# SN32F100 register map
Vendor: SONiX Technology Co., Ltd.; Series: SN32F100; File version: 1.3
CPU: CM0 r0p0, little endian, no MPU, no FPU, 2 interrupt priority bits
Registers are 32-bit, read-write, reset 0x0 unless marked. A register's access mark holds for its fields unless they carry their own. Offsets are from the block's base; [hi:lo] are bit positions; {n}, {i} and the like mark numbered series.

## SN_I2S — I2S
Base 0x4001A000
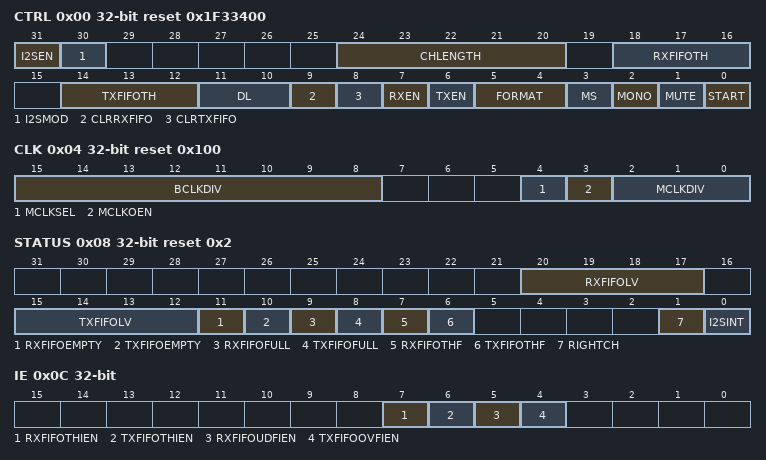
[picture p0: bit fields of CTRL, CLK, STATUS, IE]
0x00 CTRL reset 0x1F33400 — Offset:0x00 I2S Control Register
  [31] I2SEN — I2S enable
    0=Disable I2S; 1=Enable I2S
  [30] I2SMOD — I2S mode select bit
    0=I2S mode for external I2S interface; 1=Codec mode for internal I2S interface connected to ADC and DAC
  [24:20] CHLENGTH — Bit number of single channel
    {v}={v+1} bits (v=7..30); 31=32 bits (Max)
  [18:16] RXFIFOTH — Rx FIFO threshold level
    {v}=Rx FIFO threshold level={v} (v=0..7)
  [14:12] TXFIFOTH — Tx FIFO threshold level
    {v}=Tx FIFO threshold level={v} (v=0..7)
  [11:10] DL — Data length
    0=Data length=8 bits; 1=Data length=16 bits; 2=Data length=24 bits; 3=Data length=32 bits
  [9] CLRRXFIFO wo — Clear I2S RX FIFO
    0=No effect; 1=Reset Rx FIFO
  [8] CLRTXFIFO wo — Clear I2S TX FIFO
    0=No effect; 1=Reset TX FIFO
  [7] RXEN wo — Receiver enable bit
    0=Disable; 1=Enable
  [6] TXEN — Transmit enable bit
    0=Disable; 1=Enable
  [5:4] FORMAT — I2S operation format
    0=00b (Standard I2S format); 1=01b (Left-justified format); 2=10b (Right(MSB)-justified format); 3=11b (DSP mode format)
  [3] MS — Master/Slave selection bit
    0=Transmitter (Act as Master using internally generated BCLK and WS signals.); 1=Receiver (Act as Slave using externally BCLK and WS signals.)
  [2] MONO — Mono/stereo selection
    0=Stereo mode; 1=Mono mode
  [1] MUTE — Mute enable
    0=Disable mute; 1=Enable mute (I2SSDA output is 0)
  [0] START — Start Transmit/Receive
    0=Stop transmit/receive; 1=Start transmit/receive
0x04 CLK reset 0x100 — Offset:0x04 I2S Clock Register
  [15:8] BCLKDIV — BCLK divider
  [4] MCLKSEL — MLCK source selection
    0=I2S_PCLK (MCLK source of master is from I2S_PCLK); 1=Audio external high-speed X'tal (MCLK source of master is from external high-speed X'tal for Audio and Audio clock prescaler out)
  [3] MCLKOEN — MLCK output enable
    0=Disable MCLK output; 1=Enable MCLK output
  [2:0] MCLKDIV — MCLK divider
    0=MCLK=MCLK source; 1=MCLK=MCLK source/2; 2=MCLK=MCLK source/4; 3=MCLK=MCLK source/6; 4=MCLK=MCLK source/8; 5=MCLK=MCLK source/10; 6=MCLK=MCLK source/12; 7=MCLK=MCLK source/14
0x08 STATUS ro reset 0x2 — Offset:0x08 I2S Status Register
  [20:17] RXFIFOLV — RX FIFO used level
    0=0/8 RX FIFO is used (Empty); {v}={v}/8 RX FIFO is used (v=1..7); 8=8/8 RX FIFO is used (Full)
  [15:12] TXFIFOLV — TX FIFO used level
    0=0/8 TX FIFO is used (Empty); {v}={v}/8 TX FIFO is used (v=1..7); 8=8/8 TX FIFO is used (Full)
  [11] RXFIFOEMPTY — RX FIFO empty flag
    0=Not empty (RX FIFO is not empty); 1=Empty (RX FIFO is empty)
  [10] TXFIFOEMPTY — TX FIFO empty flag
    0=Not empty (TX FIFO is not empty); 1=Empty (TX FIFO is empty)
  [9] RXFIFOFULL — RX FIFO full flag
    0=Not full (RX FIFO is not full); 1=Full (RX FIFO is full)
  [8] TXFIFOFULL — TX FIFO full flag
    0=Not full (TX FIFO is not full); 1=Full (TX FIFO is full)
  [7] RXFIFOTHF — RX FIFO threshold flag
    0=RXFIFOLV is less equal than RXFIFOTH; 1=RXFIFOLV is larger than RXFIFOTH
  [6] TXFIFOTHF — TX FIFO threshold flag
    0=TXFIFOLV is larger equal than TXFIFOTH; 1=TXFIFOLV is less than TXFIFOTH
  [1] RIGHTCH — Current channel status
    0=Left (Current channel is left channel); 1=Right (Current channel is right channel)
  [0] I2SINT — I2S interrupt flag
    0=No (No I2S interrupt); 1=I2S interrupt occurs
0x0C IE — Offset:0x0C I2S Interrupt Enable Register
  [7] RXFIFOTHIEN — RX FIFO threshold interrupt enable
    0=Disable RX FIFO threshold interrupt; 1=Enable RX FIFO threshold interrupt
  [6] TXFIFOTHIEN — TX FIFO threshold interrupt enable
    0=Disable TX FIFO threshold interrupt; 1=Enable TX FIFO threshold interrupt
  [5] RXFIFOUDFIEN — RX FIFO underflow interrupt enable
    0=Disable RX FIFO underflow interrupt; 1=Enable RX FIFO underflow interrupt
  [4] TXFIFOOVFIEN — TX FIFO overflow interrupt enable
    0=Disable TX FIFO overflow interrupt; 1=Enable TX FIFO overflow interrupt
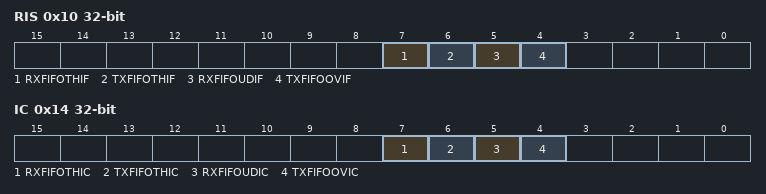
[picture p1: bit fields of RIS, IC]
0x10 RIS ro — Offset:0x10 I2S Raw Interrupt Status Register
  [7] RXFIFOTHIF — RX FIFO threshold interrupt flag
    0=No RX FIFO threshold interrupt; 1=RX FIFO threshold triggered
  [6] TXFIFOTHIF — TX FIFO threshold interrupt flag
    0=No TX FIFO threshold interrupt; 1=TX FIFO threshold triggered
  [5] RXFIFOUDIF — RX FIFO underflow interrupt flag
    0=No RX FIFO underflow; 1=RX FIFO underflow
  [4] TXFIFOOVIF — TX FIFO overflow interrupt flag
    0=No TX FIFO overflow; 1=TX FIFO overflow
0x14 IC wo — Offset:0x14 I2S Interrupt Clear Register
  [7] RXFIFOTHIC — RX FIFO threshold interrupt clear
    0=No effect; 1=Clear RXFIFOTHIF bit
  [6] TXFIFOTHIC — TX FIFO threshold interrupt clear
    0=No effect; 1=Clear TXFIFOTHIF bit
  [5] RXFIFOUDIC — RX FIFO underflow interrupt clear
    0=No effect; 1=Clear RXFIFOUDIF bit
  [4] TXFIFOOVIC — TX FIFO overflow interrupt clear
    0=No effect; 1=Clear TXFIFOOVIF bit
0x18 RXFIFO ro — Offset:0x18 UARTn RX FIFO Register
0x1C TXFIFO wo — Offset:0x1C UARTn TX FIFO Register
